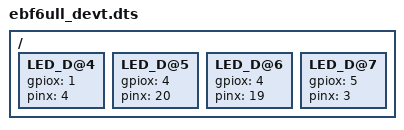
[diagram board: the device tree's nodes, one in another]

/************************************************
 * @file ebf6ull_devt.dts
 * @author Trisuborn (ttowfive@gmail.com)
 * @brief device tree for ebf6ull mini board.
 * @version 0.1
 * @date 2020-10-25
 * 
 * @copyright Copyright (c) 2020
 * 
 ************************************************/

#define EBF6ULL_LED_COMPATIBLE "imx6ull,led"

/* 根节点 */
/ {
    /* LED_Dx子节点 */
    LED_D@4 {
        compatible = EBF6ULL_LED_COMPATIBLE;
        gpiox = <1>;
        pinx  = <4>;
    };
    LED_D@5 {
        compatible = EBF6ULL_LED_COMPATIBLE;
        gpiox = <4>;
        pinx  = <20>;
    };
    LED_D@6 {
        compatible = EBF6ULL_LED_COMPATIBLE;
        gpiox = <4>;
        pinx  = <19>;
    };
    LED_D@7 {
        compatible = EBF6ULL_LED_COMPATIBLE;
        gpiox = <5>;
        pinx  = <3>;
    };
    
};
